# nrf9120 register map
Vendor: Nordic Semiconductor; Series: nrf91; File version: 1
CPU: CM33 r0p4, little endian, MPU, FPU, 3 interrupt priority bits, 69 interrupts
Registers are 32-bit, read-write, reset 0x0 unless marked. A register's access mark holds for its fields unless they carry their own. Offsets are from the block's base; [hi:lo] are bit positions; {n}, {i} and the like mark numbered series.

## WDT_NS — Watchdog Timer 0
Base 0x40018000
Same registers: WDT_S 0x50018000
0x00 TASKS_START wo — Start the watchdog
  [0] TASKS_START
    1=Trigger task
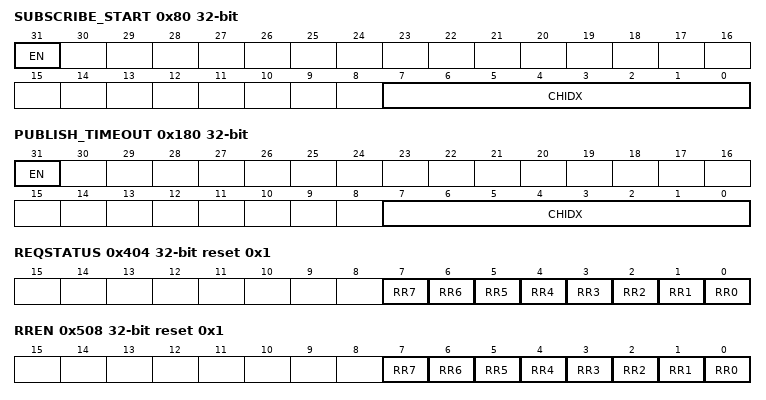
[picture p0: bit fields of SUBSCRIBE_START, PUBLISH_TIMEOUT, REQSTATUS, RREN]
0x80 SUBSCRIBE_START — Subscribe configuration for task START
  [31] EN
    0=Disabled (Disable subscription); 1=Enabled (Enable subscription)
  [7:0] CHIDX — DPPI channel that task START will subscribe to
0x100 EVENTS_TIMEOUT — Watchdog timeout
  [0] EVENTS_TIMEOUT
    0=NotGenerated (Event not generated); 1=Generated (Event generated)
0x180 PUBLISH_TIMEOUT — Publish configuration for event TIMEOUT
  [31] EN
    0=Disabled (Disable publishing); 1=Enabled (Enable publishing)
  [7:0] CHIDX — DPPI channel that event TIMEOUT will publish to
0x304 INTENSET — Enable interrupt
  [0] TIMEOUT — Write '1' to enable interrupt for event TIMEOUT
    on read: 0=Disabled (Read: Disabled); 1=Enabled (Read: Enabled) | on write: 1=Set (Enable)
0x308 INTENCLR — Disable interrupt
  [0] TIMEOUT — Write '1' to disable interrupt for event TIMEOUT
    on read: 0=Disabled (Read: Disabled); 1=Enabled (Read: Enabled) | on write: 1=Clear (Disable)
0x400 RUNSTATUS ro
  [0] RUNSTATUSWDT — Indicates whether or not the watchdog is running
    0=NotRunning (Watchdog not running); 1=Running (Watchdog is running)
0x404 REQSTATUS ro reset 0x1 — Request status
  [n] RR{n} (n=0..7) — Request status for RR[{n}] register
    0=DisabledOrRequested (RR[{n}] register is not enabled, or are already requesting reload); 1=EnabledAndUnrequested (RR[{n}] register is enabled, and are not yet requesting reload)
0x504 CRV reset 0xFFFFFFFF — Counter reload value
  [31:0] CRV — Counter reload value in number of cycles of the 32.768 kHz clock
0x508 RREN reset 0x1 — Enable register for reload request registers
  [n] RR{n} (n=0..7) — Enable or disable RR[{n}] register
    0=Disabled (Disable RR[{n}] register); 1=Enabled (Enable RR[{n}] register)
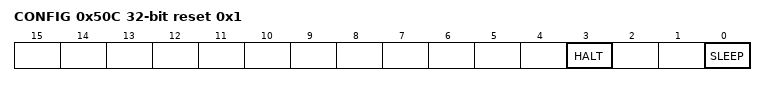
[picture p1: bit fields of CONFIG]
0x50C CONFIG reset 0x1 — Configuration register
  [3] HALT — Configure the watchdog to either be paused, or kept running, while the CPU is halted by the debugger
    0=Pause watchdog while the CPU is halted by the debugger; 1=Run (Keep the watchdog running while the CPU is halted by the debugger)
  [0] SLEEP — Configure the watchdog to either be paused, or kept running, while the CPU is sleeping
    0=Pause watchdog while the CPU is sleeping; 1=Run (Keep the watchdog running while the CPU is sleeping)
{0x600+4i} RR[{i}] (i=0..7) wo — Description collection: Reload request n
  [31:0] RR — Reload request register
    0x6E524635=Reload (Value to request a reload of the watchdog timer)

## EGU0_NS — Event generator unit 0
Base 0x4001B000
Same registers: EGU1_NS 0x4001C000, EGU2_NS 0x4001D000, EGU3_NS 0x4001E000, EGU4_NS 0x4001F000, EGU5_NS 0x40020000, EGU0_S 0x5001B000, EGU1_S 0x5001C000, EGU2_S 0x5001D000, EGU3_S 0x5001E000, EGU4_S 0x5001F000, EGU5_S 0x50020000
{0x0+4i} TASKS_TRIGGER[{i}] (i=0..15) wo — Description collection: Trigger n for triggering the corresponding TRIGGERED[n] event
  [0] TASKS_TRIGGER — Trigger n for triggering the corresponding TRIGGERED[n] event
    1=Trigger task
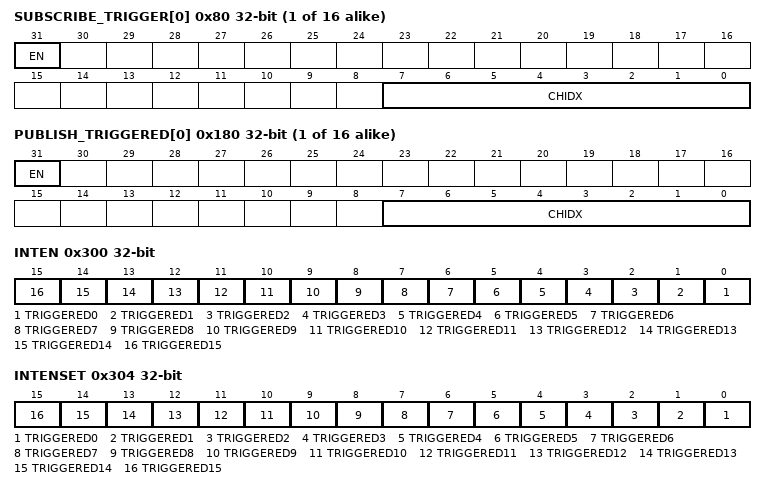
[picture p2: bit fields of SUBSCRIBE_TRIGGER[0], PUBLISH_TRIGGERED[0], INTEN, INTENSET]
{0x80+4i} SUBSCRIBE_TRIGGER[{i}] (i=0..15) — Description collection: Subscribe configuration for task TRIGGER[n]
  [31] EN
    0=Disabled (Disable subscription); 1=Enabled (Enable subscription)
  [7:0] CHIDX — DPPI channel that task TRIGGER[n] will subscribe to
{0x100+4i} EVENTS_TRIGGERED[{i}] (i=0..15) — Description collection: Event number n generated by triggering the corresponding TRIGGER[n] task
  [0] EVENTS_TRIGGERED — Event number n generated by triggering the corresponding TRIGGER[n] task
    0=NotGenerated (Event not generated); 1=Generated (Event generated)
{0x180+4i} PUBLISH_TRIGGERED[{i}] (i=0..15) — Description collection: Publish configuration for event TRIGGERED[n]
  [31] EN
    0=Disabled (Disable publishing); 1=Enabled (Enable publishing)
  [7:0] CHIDX — DPPI channel that event TRIGGERED[n] will publish to
0x300 INTEN — Enable or disable interrupt
  [all] fields
    0=Disabled; 1=Enabled
  [n] TRIGGERED{n} (n=0..15) — Enable or disable interrupt for event TRIGGERED[{n}]
0x304 INTENSET — Enable interrupt
  [all] fields
    on read: 0=Disabled (Read: Disabled); 1=Enabled (Read: Enabled) | on write: 1=Set (Enable)
  [n] TRIGGERED{n} (n=0..15) — Write '1' to enable interrupt for event TRIGGERED[{n}]
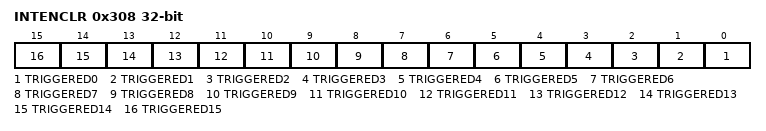
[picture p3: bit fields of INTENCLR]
0x308 INTENCLR — Disable interrupt
  [all] fields
    on read: 0=Disabled (Read: Disabled); 1=Enabled (Read: Enabled) | on write: 1=Clear (Disable)
  [n] TRIGGERED{n} (n=0..15) — Write '1' to disable interrupt for event TRIGGERED[{n}]
